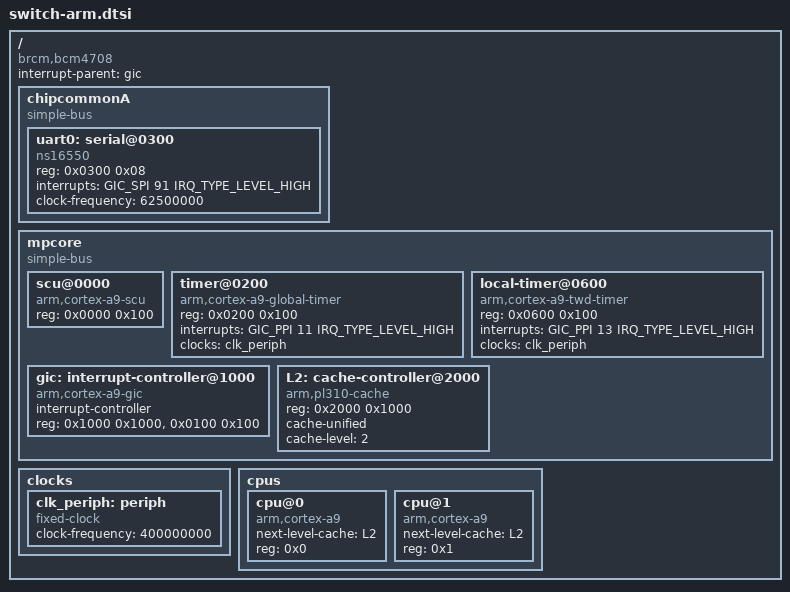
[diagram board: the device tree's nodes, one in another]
/*
 * Meraki switch-arm base file, for SoC BCM56547/8 ARM platform code
 * Common code for specific platforms.
 *
 * Copyright 2015 Cisco Systems
 * Dean Thomas <dean.thomas@meraki.com>
 *
 * Licensed under the GNU/GPL. See COPYING for details.
 */

#include <dt-bindings/interrupt-controller/irq.h>
#include <dt-bindings/interrupt-controller/arm-gic.h>
#include "skeleton.dtsi"

/ {
	compatible = "brcm,bcm4708";

	interrupt-parent = <&gic>;

	chipcommonA {
		compatible = "simple-bus";
		ranges = <0x00000000 0x18000000 0x00001000>;
		#address-cells = <1>;
		#size-cells = <1>;

		uart0: serial@0300 {
			compatible = "ns16550";
			reg = <0x0300 0x08>;
			interrupts = <GIC_SPI 91 IRQ_TYPE_LEVEL_HIGH>;
			clock-frequency = <62500000>;
			status = "okay";
		};
	};

	mpcore {
		compatible = "simple-bus";
		ranges = <0x00000000 0x19020000 0x00003000>;
		#address-cells = <1>;
		#size-cells = <1>;

		scu@0000 {
			compatible = "arm,cortex-a9-scu";
			reg = <0x0000 0x100>;
		};

		timer@0200 {
			compatible = "arm,cortex-a9-global-timer";
			reg = <0x0200 0x100>;
			interrupts = <GIC_PPI 11 IRQ_TYPE_LEVEL_HIGH>;
			clocks = <&clk_periph>;
		};

		local-timer@0600 {
			compatible = "arm,cortex-a9-twd-timer";
			reg = <0x0600 0x100>;
			interrupts = <GIC_PPI 13 IRQ_TYPE_LEVEL_HIGH>;
			clocks = <&clk_periph>;
		};

		gic: interrupt-controller@1000 {
			compatible = "arm,cortex-a9-gic";
			#interrupt-cells = <3>;
			#address-cells = <0>;
			interrupt-controller;
			reg = <0x1000 0x1000>,
			      <0x0100 0x100>;
		};

		L2: cache-controller@2000 {
			compatible = "arm,pl310-cache";
			reg = <0x2000 0x1000>;
			cache-unified;
			cache-level = <2>;
		};
	};

	clocks {
		#address-cells = <1>;
		#size-cells = <0>;

		/* As long as we do not have a real clock driver us this
		 * fixed clock */
		clk_periph: periph {
			compatible = "fixed-clock";
			#clock-cells = <0>;
			clock-frequency = <400000000>;
		};
	};
	cpus {
		#address-cells = <1>;
		#size-cells = <0>;

		cpu@0 {
			device_type = "cpu";
			compatible = "arm,cortex-a9";
			next-level-cache = <&L2>;
			reg = <0x0>;
		};

		cpu@1 {
			device_type = "cpu";
			compatible = "arm,cortex-a9";
			next-level-cache = <&L2>;
			reg = <0x1>;
		};
	};

};
